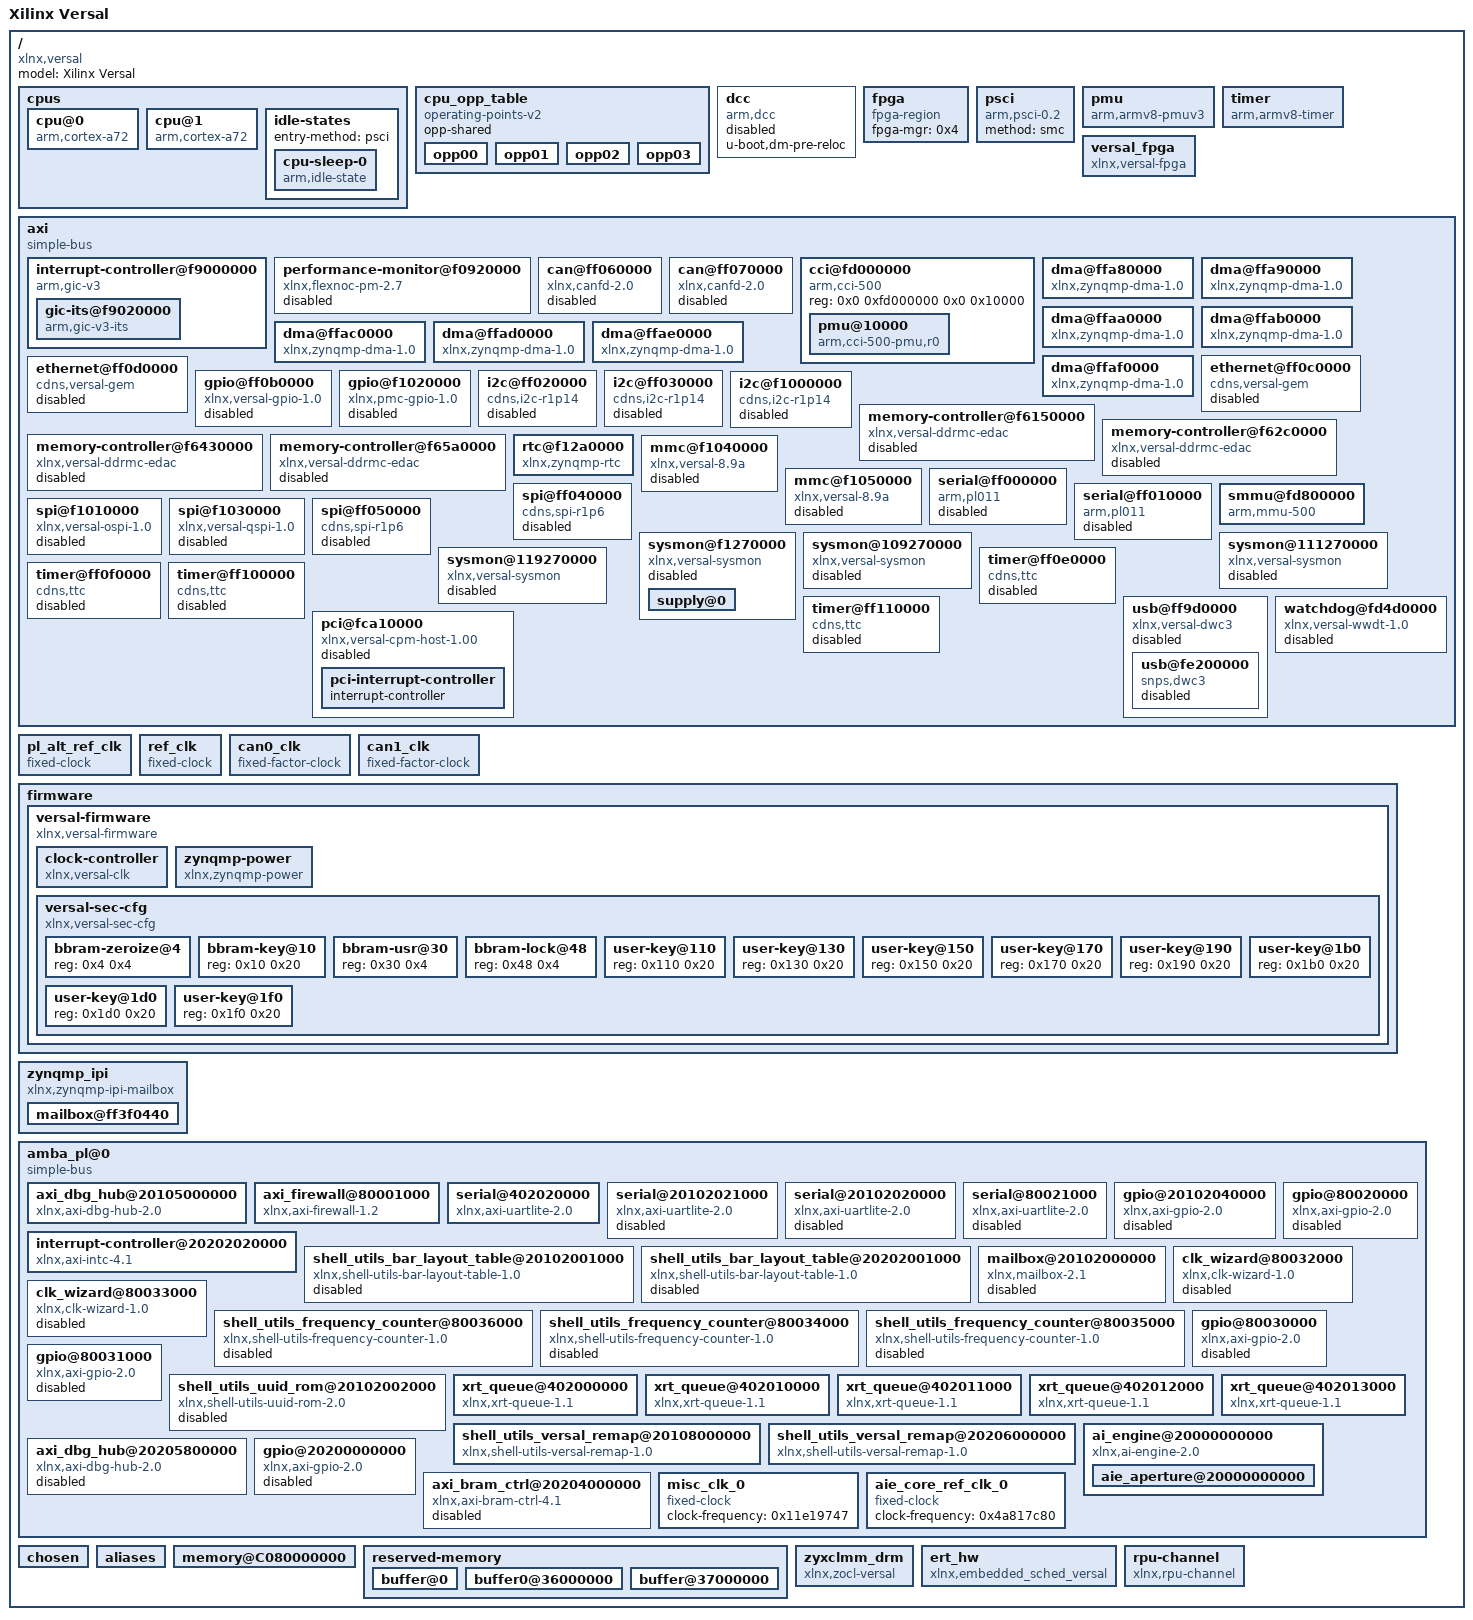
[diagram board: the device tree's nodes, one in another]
/dts-v1/;

/ {
	compatible = "xlnx,versal";
	#address-cells = <0x2>;
	#size-cells = <0x2>;
	model = "Xilinx Versal";

	cpus {
		#address-cells = <0x1>;
		#size-cells = <0x0>;

		cpu@0 {
			compatible = "arm,cortex-a72", "arm,armv8";
			device_type = "cpu";
			enable-method = "psci";
			operating-points-v2 = <0x1>;
			reg = <0x0>;
			cpu-idle-states = <0x2>;
			clocks = <0x3 0x4d>;
		};

		cpu@1 {
			compatible = "arm,cortex-a72", "arm,armv8";
			device_type = "cpu";
			enable-method = "psci";
			operating-points-v2 = <0x1>;
			reg = <0x1>;
			cpu-idle-states = <0x2>;
		};

		idle-states {
			entry-method = "psci";

			cpu-sleep-0 {
				compatible = "arm,idle-state";
				arm,psci-suspend-param = <0x40000000>;
				local-timer-stop;
				entry-latency-us = <0x12c>;
				exit-latency-us = <0x258>;
				min-residency-us = <0x2710>;
				phandle = <0x2>;
			};
		};
	};

	cpu_opp_table {
		compatible = "operating-points-v2";
		opp-shared;
		phandle = <0x1>;

		opp00 {
			opp-hz = <0x0 0x47868bf4>;
			opp-microvolt = <0xf4240>;
			clock-latency-ns = <0x7a120>;
		};

		opp01 {
			opp-hz = <0x0 0x23c345fa>;
			opp-microvolt = <0xf4240>;
			clock-latency-ns = <0x7a120>;
		};

		opp02 {
			opp-hz = <0x0 0x17d783fc>;
			opp-microvolt = <0xf4240>;
			clock-latency-ns = <0x7a120>;
		};

		opp03 {
			opp-hz = <0x0 0x11e1a2fd>;
			opp-microvolt = <0xf4240>;
			clock-latency-ns = <0x7a120>;
		};
	};

	dcc {
		compatible = "arm,dcc";
		status = "disabled";
		u-boot,dm-pre-reloc;
	};

	fpga {
		compatible = "fpga-region";
		fpga-mgr = <0x4>;
		#address-cells = <0x2>;
		#size-cells = <0x2>;
	};

	psci {
		compatible = "arm,psci-0.2";
		method = "smc";
	};

	pmu {
		compatible = "arm,armv8-pmuv3";
		interrupt-parent = <0x5>;
		interrupts = <0x1 0x7 0x304>;
	};

	timer {
		compatible = "arm,armv8-timer";
		interrupt-parent = <0x5>;
		interrupts = <0x1 0xd 0x4 0x1 0xe 0x4 0x1 0xb 0x4 0x1 0xa 0x4>;
	};

	versal_fpga {
		compatible = "xlnx,versal-fpga";
		phandle = <0x4>;
	};

	axi {
		compatible = "simple-bus";
		#address-cells = <0x2>;
		#size-cells = <0x2>;
		ranges;
		interrupt-parent = <0x5>;
		u-boot,dm-pre-reloc;

		interrupt-controller@f9000000 {
			compatible = "arm,gic-v3";
			#interrupt-cells = <0x3>;
			#address-cells = <0x2>;
			#size-cells = <0x2>;
			ranges;
			reg = <0x0 0xf9000000 0x0 0x80000 0x0 0xf9080000 0x0 0x80000>;
			interrupt-controller;
			interrupts = <0x1 0x9 0x4>;
			num_cpus = <0x2>;
			num_interrupts = <0x60>;
			phandle = <0x5>;

			gic-its@f9020000 {
				compatible = "arm,gic-v3-its";
				msi-controller;
				msi-cells = <0x1>;
				reg = <0x0 0xf9020000 0x0 0x20000>;
				phandle = <0xa>;
			};
		};

		performance-monitor@f0920000 {
			compatible = "xlnx,flexnoc-pm-2.7";
			status = "disabled";
			reg-names = "funnel", "baselpd", "basefpd";
			reg = <0x0 0xf0920000 0x0 0x1000 0x0 0xf0980000 0x0 0x9000 0x0 0xf0b80000 0x0 0x9000>;
		};

		can@ff060000 {
			compatible = "xlnx,canfd-2.0";
			status = "disabled";
			reg = <0x0 0xff060000 0x0 0x6000>;
			interrupts = <0x0 0x14 0x4>;
			clock-names = "can_clk", "s_axi_aclk";
			rx-fifo-depth = <0x40>;
			tx-mailbox-count = <0x20>;
			clocks = <0x6 0x3 0x52>;
			power-domains = <0x7 0x1822401f>;
		};

		can@ff070000 {
			compatible = "xlnx,canfd-2.0";
			status = "disabled";
			reg = <0x0 0xff070000 0x0 0x6000>;
			interrupts = <0x0 0x15 0x4>;
			clock-names = "can_clk", "s_axi_aclk";
			rx-fifo-depth = <0x40>;
			tx-mailbox-count = <0x20>;
			clocks = <0x8 0x3 0x52>;
			power-domains = <0x7 0x18224020>;
		};

		cci@fd000000 {
			compatible = "arm,cci-500";
			status = "okay";
			reg = <0x0 0xfd000000 0x0 0x10000>;
			ranges = <0x0 0x0 0xfd000000 0xa0000>;
			#address-cells = <0x1>;
			#size-cells = <0x1>;

			pmu@10000 {
				compatible = "arm,cci-500-pmu,r0";
				reg = <0x10000 0x90000>;
				interrupts = <0x0 0x6a 0x4 0x0 0x6a 0x4 0x0 0x6a 0x4 0x0 0x6a 0x4 0x0 0x6a 0x4 0x0 0x6a 0x4 0x0 0x6a 0x4 0x0 0x6a 0x4 0x0 0x6a 0x4>;
			};
		};

		dma@ffa80000 {
			compatible = "xlnx,zynqmp-dma-1.0";
			status = "okay";
			reg = <0x0 0xffa80000 0x0 0x1000>;
			interrupts = <0x0 0x3c 0x4>;
			clock-names = "clk_main", "clk_apb";
			#stream-id-cells = <0x1>;
			xlnx,bus-width = <0x40>;
			clocks = <0x3 0x51 0x3 0x52>;
			power-domains = <0x7 0x18224035>;
		};

		dma@ffa90000 {
			compatible = "xlnx,zynqmp-dma-1.0";
			status = "okay";
			reg = <0x0 0xffa90000 0x0 0x1000>;
			interrupts = <0x0 0x3d 0x4>;
			clock-names = "clk_main", "clk_apb";
			#stream-id-cells = <0x1>;
			xlnx,bus-width = <0x40>;
			clocks = <0x3 0x51 0x3 0x52>;
			power-domains = <0x7 0x18224036>;
		};

		dma@ffaa0000 {
			compatible = "xlnx,zynqmp-dma-1.0";
			status = "okay";
			reg = <0x0 0xffaa0000 0x0 0x1000>;
			interrupts = <0x0 0x3e 0x4>;
			clock-names = "clk_main", "clk_apb";
			#stream-id-cells = <0x1>;
			xlnx,bus-width = <0x40>;
			clocks = <0x3 0x51 0x3 0x52>;
			power-domains = <0x7 0x18224037>;
		};

		dma@ffab0000 {
			compatible = "xlnx,zynqmp-dma-1.0";
			status = "okay";
			reg = <0x0 0xffab0000 0x0 0x1000>;
			interrupts = <0x0 0x3f 0x4>;
			clock-names = "clk_main", "clk_apb";
			#stream-id-cells = <0x1>;
			xlnx,bus-width = <0x40>;
			clocks = <0x3 0x51 0x3 0x52>;
			power-domains = <0x7 0x18224038>;
		};

		dma@ffac0000 {
			compatible = "xlnx,zynqmp-dma-1.0";
			status = "okay";
			reg = <0x0 0xffac0000 0x0 0x1000>;
			interrupts = <0x0 0x40 0x4>;
			clock-names = "clk_main", "clk_apb";
			#stream-id-cells = <0x1>;
			xlnx,bus-width = <0x40>;
			clocks = <0x3 0x51 0x3 0x52>;
			power-domains = <0x7 0x18224039>;
		};

		dma@ffad0000 {
			compatible = "xlnx,zynqmp-dma-1.0";
			status = "okay";
			reg = <0x0 0xffad0000 0x0 0x1000>;
			interrupts = <0x0 0x41 0x4>;
			clock-names = "clk_main", "clk_apb";
			#stream-id-cells = <0x1>;
			xlnx,bus-width = <0x40>;
			clocks = <0x3 0x51 0x3 0x52>;
			power-domains = <0x7 0x1822403a>;
		};

		dma@ffae0000 {
			compatible = "xlnx,zynqmp-dma-1.0";
			status = "okay";
			reg = <0x0 0xffae0000 0x0 0x1000>;
			interrupts = <0x0 0x42 0x4>;
			clock-names = "clk_main", "clk_apb";
			#stream-id-cells = <0x1>;
			xlnx,bus-width = <0x40>;
			clocks = <0x3 0x51 0x3 0x52>;
			power-domains = <0x7 0x1822403b>;
		};

		dma@ffaf0000 {
			compatible = "xlnx,zynqmp-dma-1.0";
			status = "okay";
			reg = <0x0 0xffaf0000 0x0 0x1000>;
			interrupts = <0x0 0x43 0x4>;
			clock-names = "clk_main", "clk_apb";
			#stream-id-cells = <0x1>;
			xlnx,bus-width = <0x40>;
			clocks = <0x3 0x51 0x3 0x52>;
			power-domains = <0x7 0x1822403c>;
		};

		ethernet@ff0c0000 {
			compatible = "cdns,versal-gem", "cdns,gem";
			status = "disabled";
			reg = <0x0 0xff0c0000 0x0 0x1000>;
			interrupts = <0x0 0x38 0x4 0x0 0x38 0x4>;
			clock-names = "pclk", "hclk", "tx_clk", "rx_clk", "tsu_clk";
			#stream-id-cells = <0x1>;
			#address-cells = <0x1>;
			#size-cells = <0x0>;
			clocks = <0x3 0x52 0x3 0x58 0x3 0x31 0x3 0x30 0x3 0x2b>;
			power-domains = <0x7 0x18224019>;
		};

		ethernet@ff0d0000 {
			compatible = "cdns,versal-gem", "cdns,gem";
			status = "disabled";
			reg = <0x0 0xff0d0000 0x0 0x1000>;
			interrupts = <0x0 0x3a 0x4 0x0 0x3a 0x4>;
			clock-names = "pclk", "hclk", "tx_clk", "rx_clk", "tsu_clk";
			#stream-id-cells = <0x1>;
			#address-cells = <0x1>;
			#size-cells = <0x0>;
			clocks = <0x3 0x52 0x3 0x59 0x3 0x33 0x3 0x32 0x3 0x2b>;
			power-domains = <0x7 0x1822401a>;
		};

		gpio@ff0b0000 {
			compatible = "xlnx,versal-gpio-1.0";
			status = "disabled";
			reg = <0x0 0xff0b0000 0x0 0x1000>;
			interrupts = <0x0 0xd 0x4>;
			#gpio-cells = <0x2>;
			gpio-controller;
			#interrupt-cells = <0x2>;
			interrupt-controller;
			clocks = <0x3 0x52>;
			power-domains = <0x7 0x18224023>;
		};

		gpio@f1020000 {
			compatible = "xlnx,pmc-gpio-1.0";
			status = "disabled";
			reg = <0x0 0xf1020000 0x0 0x1000>;
			interrupts = <0x0 0x7a 0x4>;
			#gpio-cells = <0x2>;
			gpio-controller;
			#interrupt-cells = <0x2>;
			interrupt-controller;
			clocks = <0x3 0x3d>;
			power-domains = <0x7 0x1822402c>;
		};

		i2c@ff020000 {
			compatible = "cdns,i2c-r1p14", "cdns,i2c-r1p10";
			status = "disabled";
			reg = <0x0 0xff020000 0x0 0x1000>;
			interrupts = <0x0 0xe 0x4>;
			clock-frequency = <0x61a80>;
			#address-cells = <0x1>;
			#size-cells = <0x0>;
			clocks = <0x3 0x62>;
			power-domains = <0x7 0x1822401d>;
		};

		i2c@ff030000 {
			compatible = "cdns,i2c-r1p14", "cdns,i2c-r1p10";
			status = "disabled";
			reg = <0x0 0xff030000 0x0 0x1000>;
			interrupts = <0x0 0xf 0x4>;
			clock-frequency = <0x61a80>;
			#address-cells = <0x1>;
			#size-cells = <0x0>;
			clocks = <0x3 0x63>;
			power-domains = <0x7 0x1822401e>;
		};

		i2c@f1000000 {
			compatible = "cdns,i2c-r1p14", "cdns,i2c-r1p10";
			status = "disabled";
			reg = <0x0 0xf1000000 0x0 0x1000>;
			interrupts = <0x0 0x7b 0x4>;
			clock-frequency = <0x61a80>;
			#address-cells = <0x1>;
			#size-cells = <0x0>;
			clocks = <0x3 0x3e>;
			power-domains = <0x7 0x1822402d>;
		};

		memory-controller@f6150000 {
			compatible = "xlnx,versal-ddrmc-edac";
			status = "disabled";
			reg = <0x0 0xf6150000 0x0 0x2000 0x0 0xf6070000 0x0 0x20000>;
			reg-names = "ddrmc_base", "ddrmc_noc_base";
			interrupts = <0x0 0x93 0x4>;
			xlnx,mc-id = <0x0>;
		};

		memory-controller@f62c0000 {
			compatible = "xlnx,versal-ddrmc-edac";
			status = "disabled";
			reg = <0x0 0xf62c0000 0x0 0x2000 0x0 0xf6210000 0x0 0x20000>;
			reg-names = "ddrmc_base", "ddrmc_noc_base";
			interrupts = <0x0 0x93 0x4>;
			xlnx,mc-id = <0x1>;
		};

		memory-controller@f6430000 {
			compatible = "xlnx,versal-ddrmc-edac";
			status = "disabled";
			reg = <0x0 0xf6430000 0x0 0x2000 0x0 0xf6380000 0x0 0x20000>;
			reg-names = "ddrmc_base", "ddrmc_noc_base";
			interrupts = <0x0 0x93 0x4>;
			xlnx,mc-id = <0x2>;
		};

		memory-controller@f65a0000 {
			compatible = "xlnx,versal-ddrmc-edac";
			status = "disabled";
			reg = <0x0 0xf65a0000 0x0 0x2000 0x0 0xf64f0000 0x0 0x20000>;
			reg-names = "ddrmc_base", "ddrmc_noc_base";
			interrupts = <0x0 0x93 0x4>;
			xlnx,mc-id = <0x3>;
		};

		rtc@f12a0000 {
			compatible = "xlnx,zynqmp-rtc";
			status = "okay";
			reg = <0x0 0xf12a0000 0x0 0x100>;
			interrupt-names = "alarm", "sec";
			interrupts = <0x0 0x8e 0x4 0x0 0x8f 0x4>;
			calibration = <0x7fff>;
			power-domains = <0x7 0x18224034>;
		};

		mmc@f1040000 {
			compatible = "xlnx,versal-8.9a", "arasan,sdhci-8.9a";
			status = "disabled";
			reg = <0x0 0xf1040000 0x0 0x10000>;
			interrupts = <0x0 0x7e 0x4>;
			clock-names = "clk_xin", "clk_ahb";
			xlnx,device_id = <0x0>;
			#stream-id-cells = <0x1>;
			#clock-cells = <0x1>;
			clock-output-names = "clk_out_sd0", "clk_in_sd0";
			clocks = <0x3 0x3b 0x3 0x52>;
			power-domains = <0x7 0x1822402e>;
		};

		mmc@f1050000 {
			compatible = "xlnx,versal-8.9a", "arasan,sdhci-8.9a";
			status = "disabled";
			reg = <0x0 0xf1050000 0x0 0x10000>;
			interrupts = <0x0 0x80 0x4>;
			clock-names = "clk_xin", "clk_ahb";
			xlnx,device_id = <0x1>;
			#stream-id-cells = <0x1>;
			#clock-cells = <0x1>;
			clock-output-names = "clk_out_sd1", "clk_in_sd1";
			clocks = <0x3 0x3c 0x3 0x52>;
			power-domains = <0x7 0x1822402f>;
		};

		serial@ff000000 {
			compatible = "arm,pl011", "arm,sbsa-uart";
			status = "disabled";
			reg = <0x0 0xff000000 0x0 0x1000>;
			interrupts = <0x0 0x12 0x4>;
			clock-names = "uart_clk", "apb_clk";
			current-speed = <0x1c200>;
			u-boot,dm-pre-reloc;
			clocks = <0x3 0x5c 0x3 0x52>;
			power-domains = <0x7 0x18224021>;
			cts-override;
			device_type = "serial";
			port-number = <0x1>;
		};

		serial@ff010000 {
			compatible = "arm,pl011", "arm,sbsa-uart";
			status = "disabled";
			reg = <0x0 0xff010000 0x0 0x1000>;
			interrupts = <0x0 0x13 0x4>;
			clock-names = "uart_clk", "apb_clk";
			current-speed = <0x1c200>;
			u-boot,dm-pre-reloc;
			clocks = <0x3 0x5d 0x3 0x52>;
			power-domains = <0x7 0x18224022>;
			cts-override;
			device_type = "serial";
			port-number = <0x2>;
		};

		smmu@fd800000 {
			compatible = "arm,mmu-500";
			status = "okay";
			reg = <0x0 0xfd800000 0x0 0x40000>;
			stream-match-mask = <0x7c00>;
			#iommu-cells = <0x1>;
			#global-interrupts = <0x1>;
			interrupts = <0x0 0x6b 0x4 0x0 0x6b 0x4 0x0 0x6b 0x4 0x0 0x6b 0x4 0x0 0x6b 0x4 0x0 0x6b 0x4 0x0 0x6b 0x4 0x0 0x6b 0x4 0x0 0x6b 0x4 0x0 0x6b 0x4 0x0 0x6b 0x4 0x0 0x6b 0x4 0x0 0x6b 0x4 0x0 0x6b 0x4 0x0 0x6b 0x4 0x0 0x6b 0x4 0x0 0x6b 0x4 0x0 0x6b 0x4 0x0 0x6b 0x4 0x0 0x6b 0x4 0x0 0x6b 0x4 0x0 0x6b 0x4 0x0 0x6b 0x4 0x0 0x6b 0x4 0x0 0x6b 0x4 0x0 0x6b 0x4 0x0 0x6b 0x4 0x0 0x6b 0x4 0x0 0x6b 0x4 0x0 0x6b 0x4 0x0 0x6b 0x4 0x0 0x6b 0x4 0x0 0x6b 0x4>;
		};

		spi@f1010000 {
			compatible = "xlnx,versal-ospi-1.0", "cadence,qspi", "cdns,qspi-nor";
			status = "disabled";
			reg = <0x0 0xf1010000 0x0 0x10000 0x0 0xc0000000 0x0 0x20000000>;
			interrupts = <0x0 0x7c 0x4 0x0 0x7c 0x4>;
			cdns,fifo-depth = <0x100>;
			cdns,fifo-width = <0x4>;
			cdns,is-dma = <0x1>;
			cdns,is-stig-pgm = <0x1>;
			cdns,trigger-address = <0xc0000000>;
			#stream-id-cells = <0x1>;
			#address-cells = <0x1>;
			#size-cells = <0x0>;
			clocks = <0x3 0x3a>;
			power-domains = <0x7 0x1822402a>;
			is-dual = <0x0>;
			is-stacked = <0x0>;
		};

		spi@f1030000 {
			compatible = "xlnx,versal-qspi-1.0";
			status = "disabled";
			reg = <0x0 0xf1030000 0x0 0x1000>;
			interrupts = <0x0 0x7d 0x4 0x0 0x7d 0x4>;
			clock-names = "ref_clk", "pclk";
			#stream-id-cells = <0x1>;
			#address-cells = <0x1>;
			#size-cells = <0x0>;
			clocks = <0x3 0x39 0x3 0x52>;
			power-domains = <0x7 0x1822402b>;
		};

		spi@ff040000 {
			compatible = "cdns,spi-r1p6";
			status = "disabled";
			reg = <0x0 0xff040000 0x0 0x1000>;
			interrupts = <0x0 0x10 0x4>;
			clock-names = "ref_clk", "pclk";
			#address-cells = <0x1>;
			#size-cells = <0x0>;
			clocks = <0x3 0x5e 0x3 0x52>;
			power-domains = <0x7 0x1822401b>;
		};

		spi@ff050000 {
			compatible = "cdns,spi-r1p6";
			status = "disabled";
			reg = <0x0 0xff050000 0x0 0x1000>;
			interrupts = <0x0 0x11 0x4>;
			clock-names = "ref_clk", "pclk";
			#address-cells = <0x1>;
			#size-cells = <0x0>;
			clocks = <0x3 0x5f 0x3 0x52>;
			power-domains = <0x7 0x1822401c>;
		};

		sysmon@f1270000 {
			compatible = "xlnx,versal-sysmon";
			status = "disabled";
			reg = <0x0 0xf1270000 0x0 0x4000>;
			interrupts = <0x0 0x90 0x4>;
			xlnx,numchannels = [01];
			#address-cells = <0x1>;
			#size-cells = <0x0>;

			supply@0 {
				reg = <0x0>;
				xlnx,name = "vccint";
			};
		};

		sysmon@109270000 {
			compatible = "xlnx,versal-sysmon";
			#address-cells = <0x2>;
			#size-cells = <0x2>;
			status = "disabled";
			reg = <0x1 0x9270000 0x0 0x4000>;
			xlnx,numchannels = [00];
		};

		sysmon@111270000 {
			compatible = "xlnx,versal-sysmon";
			#address-cells = <0x2>;
			#size-cells = <0x2>;
			status = "disabled";
			reg = <0x1 0x11270000 0x0 0x4000>;
			xlnx,numchannels = [00];
		};

		sysmon@119270000 {
			compatible = "xlnx,versal-sysmon";
			#address-cells = <0x2>;
			#size-cells = <0x2>;
			status = "disabled";
			reg = <0x1 0x19270000 0x0 0x4000>;
			xlnx,numchannels = [00];
		};

		timer@ff0e0000 {
			compatible = "cdns,ttc";
			status = "disabled";
			interrupts = <0x0 0x25 0x4 0x0 0x26 0x4 0x0 0x27 0x4>;
			reg = <0x0 0xff0e0000 0x0 0x1000>;
			timer-width = <0x20>;
			clocks = <0x3 0x27 0x3 0x52>;
			power-domains = <0x7 0x18224024>;
		};

		timer@ff0f0000 {
			compatible = "cdns,ttc";
			status = "disabled";
			interrupts = <0x0 0x28 0x4 0x0 0x29 0x4 0x0 0x2a 0x4>;
			reg = <0x0 0xff0f0000 0x0 0x1000>;
			timer-width = <0x20>;
			clocks = <0x3 0x28 0x3 0x52>;
			power-domains = <0x7 0x18224025>;
		};

		timer@ff100000 {
			compatible = "cdns,ttc";
			status = "disabled";
			interrupts = <0x0 0x2b 0x4 0x0 0x2c 0x4 0x0 0x2d 0x4>;
			reg = <0x0 0xff100000 0x0 0x1000>;
			timer-width = <0x20>;
			clocks = <0x3 0x29 0x3 0x52>;
			power-domains = <0x7 0x18224026>;
		};

		timer@ff110000 {
			compatible = "cdns,ttc";
			status = "disabled";
			interrupts = <0x0 0x2e 0x4 0x0 0x2f 0x4 0x0 0x30 0x4>;
			reg = <0x0 0xff110000 0x0 0x1000>;
			timer-width = <0x20>;
			clocks = <0x3 0x2a 0x3 0x52>;
			power-domains = <0x7 0x18224027>;
		};

		usb@ff9d0000 {
			compatible = "xlnx,versal-dwc3";
			status = "disabled";
			reg = <0x0 0xff9d0000 0x0 0x100>;
			clock-names = "bus_clk", "ref_clk";
			ranges;
			#address-cells = <0x2>;
			#size-cells = <0x2>;
			clocks = <0x3 0x5b 0x3 0x68>;
			power-domains = <0x7 0x18224018>;

			usb@fe200000 {
				compatible = "snps,dwc3";
				status = "disabled";
				reg = <0x0 0xfe200000 0x0 0x10000>;
				interrupt-names = "dwc_usb3", "otg", "usb-wakeup";
				interrupts = <0x0 0x16 0x4 0x0 0x1a 0x4 0x0 0x4a 0x4>;
				#stream-id-cells = <0x1>;
				snps,dis_u2_susphy_quirk;
				snps,dis_u3_susphy_quirk;
				snps,quirk-frame-length-adjustment = <0x20>;
				snps,refclk_fladj;
				snps,mask_phy_reset;
			};
		};

		pci@fca10000 {
			#address-cells = <0x3>;
			#interrupt-cells = <0x1>;
			#size-cells = <0x2>;
			compatible = "xlnx,versal-cpm-host-1.00";
			status = "disabled";
			interrupt-map = <0x0 0x0 0x0 0x1 0x9 0x0 0x0 0x0 0x0 0x2 0x9 0x1 0x0 0x0 0x0 0x3 0x9 0x2 0x0 0x0 0x0 0x4 0x9 0x3>;
			interrupt-map-mask = <0x0 0x0 0x0 0x7>;
			interrupt-names = "misc";
			interrupts = <0x0 0x48 0x4>;
			ranges = <0x2000000 0x0 0xe0000000 0x0 0xe0000000 0x0 0x10000000 0x43000000 0x80 0x0 0x80 0x0 0x0 0x80000000>;
			msi-map = <0x0 0xa 0x0 0x10000>;
			reg = <0x0 0xfca10000 0x0 0x1000 0x6 0x0 0x0 0x1000000>;
			reg-names = "cpm_slcr", "cfg";

			pci-interrupt-controller {
				#address-cells = <0x0>;
				#interrupt-cells = <0x1>;
				interrupt-controller;
				phandle = <0x9>;
			};
		};

		watchdog@fd4d0000 {
			compatible = "xlnx,versal-wwdt-1.0";
			status = "disabled";
			reg = <0x0 0xfd4d0000 0x0 0x10000>;
			interrupt-names = "wdt", "wwdt_reset_pending";
			interrupts = <0x0 0x64 0x1 0x0 0x6d 0x1>;
			timeout-sec = <0x1e>;
			pretimeout-sec = <0x19>;
			clocks = <0x3 0x52>;
			power-domains = <0x7 0x18224029>;
		};
	};

	pl_alt_ref_clk {
		u-boot,dm-pre-reloc;
		compatible = "fixed-clock";
		#clock-cells = <0x0>;
		clock-frequency = <0x1fca055>;
		phandle = <0xc>;
	};

	ref_clk {
		u-boot,dm-pre-reloc;
		compatible = "fixed-clock";
		#clock-cells = <0x0>;
		clock-frequency = <0x1fca055>;
		phandle = <0xb>;
	};

	can0_clk {
		#clock-cells = <0x0>;
		compatible = "fixed-factor-clock";
		clocks = <0x3 0x60>;
		clock-div = <0x2>;
		clock-mult = <0x1>;
		phandle = <0x6>;
	};

	can1_clk {
		#clock-cells = <0x0>;
		compatible = "fixed-factor-clock";
		clocks = <0x3 0x61>;
		clock-div = <0x2>;
		clock-mult = <0x1>;
		phandle = <0x8>;
	};

	firmware {

		versal-firmware {
			compatible = "xlnx,versal-firmware";
			interrupt-parent = <0x5>;
			u-boot,dm-pre-reloc;
			method = "smc";
			#power-domain-cells = <0x1>;
			phandle = <0x7>;

			clock-controller {
				u-boot,dm-pre-reloc;
				#clock-cells = <0x1>;
				compatible = "xlnx,versal-clk";
				clocks = <0xb 0xc>;
				clock-names = "ref_clk", "pl_alt_ref_clk";
				phandle = <0x3>;
			};

			zynqmp-power {
				compatible = "xlnx,zynqmp-power";
				interrupt-parent = <0x5>;
				interrupts = <0x0 0x1e 0x4>;
				mboxes = <0xd 0x0 0xd 0x1>;
				mbox-names = "tx", "rx";
			};

			versal-sec-cfg {
				compatible = "xlnx,versal-sec-cfg";
				#address-cells = <0x1>;
				#size-cells = <0x1>;

				bbram-zeroize@4 {
					reg = <0x4 0x4>;
				};

				bbram-key@10 {
					reg = <0x10 0x20>;
				};

				bbram-usr@30 {
					reg = <0x30 0x4>;
				};

				bbram-lock@48 {
					reg = <0x48 0x4>;
				};

				user-key@110 {
					reg = <0x110 0x20>;
				};

				user-key@130 {
					reg = <0x130 0x20>;
				};

				user-key@150 {
					reg = <0x150 0x20>;
				};

				user-key@170 {
					reg = <0x170 0x20>;
				};

				user-key@190 {
					reg = <0x190 0x20>;
				};

				user-key@1b0 {
					reg = <0x1b0 0x20>;
				};

				user-key@1d0 {
					reg = <0x1d0 0x20>;
				};

				user-key@1f0 {
					reg = <0x1f0 0x20>;
				};
			};
		};
	};

	zynqmp_ipi {
		compatible = "xlnx,zynqmp-ipi-mailbox";
		interrupt-parent = <0x5>;
		interrupts = <0x0 0x1e 0x4>;
		xlnx,ipi-id = <0x2>;
		#address-cells = <0x2>;
		#size-cells = <0x2>;
		ranges;

		mailbox@ff3f0440 {
			reg = <0x0 0xff3f0440 0x0 0x20 0x0 0xff3f0460 0x0 0x20 0x0 0xff3f0280 0x0 0x20 0x0 0xff3f02a0 0x0 0x20>;
			reg-names = "local_request_region", "local_response_region", "remote_request_region", "remote_response_region";
			#mbox-cells = <0x1>;
			xlnx,ipi-id = <0x1>;
			phandle = <0xd>;
		};
	};

	amba_pl@0 {
		#address-cells = <0x2>;
		#size-cells = <0x2>;
		compatible = "simple-bus";
		ranges;

		axi_dbg_hub@20105000000 {
			clock-names = "aclk";
			clocks = <0x3 0x41>;
			compatible = "xlnx,axi-dbg-hub-2.0";
			reg = <0x201 0x5000000 0x0 0x200000>;
			xlnx,addr-offset = <0x201 0x5000000>;
			xlnx,addr-range = <0x200000>;
			xlnx,axi-addr-width = <0x40>;
			xlnx,axi-data-width = <0x80>;
			xlnx,axi-id-width = <0x2>;
			xlnx,axis-tdata-width = <0x20>;
			xlnx,num-debug-cores = <0x0>;
			xlnx,num-rd-outstanding-txn = <0x1>;
			xlnx,num-wr-outstanding-txn = <0x1>;
		};

		axi_firewall@80001000 {
			clock-names = "aclk";
			clocks = <0x3 0x41>;
			compatible = "xlnx,axi-firewall-1.2";
			reg = <0x0 0x80001000 0x0 0x1000>;
			xlnx,addr-width = <0x40>;
			xlnx,aruser-width = <0x0>;
			xlnx,awuser-width = <0x0>;
			xlnx,buser-width = <0x0>;
			xlnx,enable-ctl-clock = <0x0>;
			xlnx,enable-initial-delay = <0x1>;
			xlnx,enable-pipelining = <0x1>;
			xlnx,enable-prescaler = <0x1>;
			xlnx,enable-protocol-checks = <0x1>;
			xlnx,enable-timeout-checks = <0x1>;
			xlnx,firewall-mode = <0x0>;
			xlnx,id-width = <0x0>;
			xlnx,mask-err-resp = <0x1>;
			xlnx,num-read-outstanding = <0x20>;
			xlnx,num-read-threads = <0x1>;
			xlnx,num-write-outstanding = <0x20>;
			xlnx,num-write-threads = <0x1>;
			xlnx,protocol = <0x2>;
			xlnx,rdata-width = <0x20>;
			xlnx,ruser-width = <0x0>;
			xlnx,wdata-width = <0x20>;
			xlnx,wuser-width = <0x0>;
		};

		serial@402020000 {
			clock-names = "s_axi_aclk";
			clocks = <0x3 0x41>;
			compatible = "xlnx,axi-uartlite-2.0", "xlnx,xps-uartlite-1.00.a";
			current-speed = <0x38400>;
			device_type = "serial";
			interrupt-names = "interrupt";
			interrupt-parent = <0x5>;
			interrupts = <0x0 0x5e 0x1>;
			port-number = <0x0>;
			reg = <0x4 0x2020000 0x0 0x1000>;
			xlnx,baudrate = <0x38400>;
			xlnx,data-bits = <0x8>;
			xlnx,odd-parity = <0x0>;
			xlnx,s-axi-aclk-freq-hz-d = "100.0";
			xlnx,use-parity = <0x0>;
		};

		serial@20102021000 {
			status = "disabled";
			clock-names = "s_axi_aclk";
			clocks = <0x3 0x41>;
			compatible = "xlnx,axi-uartlite-2.0", "xlnx,xps-uartlite-1.00.a";
			current-speed = <0x38400>;
			device_type = "serial";
			port-number = <0x2>;
			reg = <0x201 0x2021000 0x0 0x1000>;
			xlnx,baudrate = <0x38400>;
			xlnx,data-bits = <0x8>;
			xlnx,odd-parity = <0x0>;
			xlnx,s-axi-aclk-freq-hz-d = "100.0";
			xlnx,use-parity = <0x0>;
		};

		serial@20102020000 {
			status = "disabled";
			clock-names = "s_axi_aclk";
			clocks = <0x3 0x41>;
			compatible = "xlnx,axi-uartlite-2.0", "xlnx,xps-uartlite-1.00.a";
			current-speed = <0x38400>;
			device_type = "serial";
			port-number = <0x3>;
			reg = <0x201 0x2020000 0x0 0x1000>;
			xlnx,baudrate = <0x38400>;
			xlnx,data-bits = <0x8>;
			xlnx,odd-parity = <0x0>;
			xlnx,s-axi-aclk-freq-hz-d = "100.0";
			xlnx,use-parity = <0x0>;
		};

		serial@80021000 {
			status = "disabled";
			clock-names = "s_axi_aclk";
			clocks = <0x3 0x41>;
			compatible = "xlnx,axi-uartlite-2.0", "xlnx,xps-uartlite-1.00.a";
			current-speed = <0x38400>;
			device_type = "serial";
			interrupt-names = "interrupt";
			interrupt-parent = <0x5>;
			interrupts = <0x0 0x57 0x1>;
			port-number = <0x4>;
			reg = <0x0 0x80021000 0x0 0x1000>;
			xlnx,baudrate = <0x38400>;
			xlnx,data-bits = <0x8>;
			xlnx,odd-parity = <0x0>;
			xlnx,s-axi-aclk-freq-hz-d = "100.0";
			xlnx,use-parity = <0x0>;
		};

		gpio@20102040000 {
			status = "disabled";
			#gpio-cells = <0x2>;
			clock-names = "s_axi_aclk";
			clocks = <0x3 0x41>;
			compatible = "xlnx,axi-gpio-2.0", "xlnx,xps-gpio-1.00.a";
			gpio-controller;
			reg = <0x201 0x2040000 0x0 0x1000>;
			xlnx,all-inputs = <0x0>;
			xlnx,all-inputs-2 = <0x1>;
			xlnx,all-outputs = <0x1>;
			xlnx,all-outputs-2 = <0x0>;
			xlnx,dout-default = <0x0>;
			xlnx,dout-default-2 = <0x0>;
			xlnx,gpio-width = <0x1>;
			xlnx,gpio2-width = <0x1>;
			xlnx,interrupt-present = <0x0>;
			xlnx,is-dual = <0x1>;
			xlnx,tri-default = <0xffffffff>;
			xlnx,tri-default-2 = <0xffffffff>;
		};

		gpio@80020000 {
			status = "disabled";
			#gpio-cells = <0x2>;
			clock-names = "s_axi_aclk";
			clocks = <0x3 0x41>;
			compatible = "xlnx,axi-gpio-2.0", "xlnx,xps-gpio-1.00.a";
			gpio-controller;
			reg = <0x0 0x80020000 0x0 0x1000>;
			xlnx,all-inputs = <0x0>;
			xlnx,all-inputs-2 = <0x1>;
			xlnx,all-outputs = <0x1>;
			xlnx,all-outputs-2 = <0x0>;
			xlnx,dout-default = <0x0>;
			xlnx,dout-default-2 = <0x0>;
			xlnx,gpio-width = <0x2>;
			xlnx,gpio2-width = <0x2>;
			xlnx,interrupt-present = <0x0>;
			xlnx,is-dual = <0x1>;
			xlnx,tri-default = <0xffffffff>;
			xlnx,tri-default-2 = <0xffffffff>;
		};

		interrupt-controller@20202020000 {
			#interrupt-cells = <0x2>;
			clock-names = "s_axi_aclk";
			clocks = <0x3 0x41>;
			compatible = "xlnx,axi-intc-4.1", "xlnx,xps-intc-1.00.a";
			interrupt-controller;
			interrupt-names = "irq";
			interrupt-parent = <0x5>;
			interrupts = <0x0 0x5d 0x4>;
			reg = <0x202 0x2020000 0x0 0x1000>;
			xlnx,kind-of-intr = <0xffffffff>;
			xlnx,num-intr-inputs = <0x20>;
		};

		shell_utils_bar_layout_table@20102001000 {
			status = "disabled";
			clock-names = "S_AXI_ACLK";
			clocks = <0x3 0x41>;
			compatible = "xlnx,shell-utils-bar-layout-table-1.0";
			reg = <0x201 0x2001000 0x0 0x1000>;
			xlnx,entry-addr-0 = <0x0 0x2002000>;
			xlnx,entry-addr-1 = <0x0 0x2000000>;
			xlnx,entry-addr-2 = <0x0 0x2010000>;
			xlnx,entry-addr-3 = <0x0 0x8000000>;
			xlnx,entry-addr-4 = <0x0 0x0>;
			xlnx,entry-addr-5 = <0x0 0x0>;
			xlnx,entry-bar-0 = <0x0>;
			xlnx,entry-bar-1 = <0x0>;
			xlnx,entry-bar-2 = <0x0>;
			xlnx,entry-bar-3 = <0x0>;
			xlnx,entry-bar-4 = <0x0>;
			xlnx,entry-bar-5 = <0x0>;
			xlnx,entry-major-version-0 = <0x1>;
			xlnx,entry-major-version-1 = <0x1>;
			xlnx,entry-major-version-2 = <0x1>;
			xlnx,entry-major-version-3 = <0x1>;
			xlnx,entry-major-version-4 = <0x0>;
			xlnx,entry-major-version-5 = <0x0>;
			xlnx,entry-minor-version-0 = <0x0>;
			xlnx,entry-minor-version-1 = <0x0>;
			xlnx,entry-minor-version-2 = <0x1>;
			xlnx,entry-minor-version-3 = <0x0>;
			xlnx,entry-minor-version-4 = <0x0>;
			xlnx,entry-minor-version-5 = <0x0>;
			xlnx,entry-rsvd0-0 = <0x0>;
			xlnx,entry-rsvd0-1 = <0x3>;
			xlnx,entry-rsvd0-2 = <0x0>;
			xlnx,entry-rsvd0-3 = <0x0>;
			xlnx,entry-rsvd0-4 = <0x0>;
			xlnx,entry-rsvd0-5 = <0x0>;
			xlnx,entry-type-0 = <0x50>;
			xlnx,entry-type-1 = <0x53>;
			xlnx,entry-type-2 = <0x54>;
			xlnx,entry-type-3 = <0x55>;
			xlnx,entry-type-4 = <0x0>;
			xlnx,entry-type-5 = <0x0>;
			xlnx,entry-version-type-0 = <0x1>;
			xlnx,entry-version-type-1 = <0x1>;
			xlnx,entry-version-type-2 = <0x1>;
			xlnx,entry-version-type-3 = <0x1>;
			xlnx,entry-version-type-4 = <0x0>;
			xlnx,entry-version-type-5 = <0x0>;
			xlnx,num-table-entries = <0x4>;
			xlnx,xdevicefamily = "versal";
		};

		shell_utils_bar_layout_table@20202001000 {
			status = "disabled";
			clock-names = "S_AXI_ACLK";
			clocks = <0x3 0x41>;
			compatible = "xlnx,shell-utils-bar-layout-table-1.0";
			reg = <0x202 0x2001000 0x0 0x1000>;
			xlnx,entry-addr-0 = <0x0 0x2000000>;
			xlnx,entry-addr-1 = <0x0 0x0>;
			xlnx,entry-addr-2 = <0x0 0x0>;
			xlnx,entry-addr-3 = <0x0 0x0>;
			xlnx,entry-addr-4 = <0x0 0x0>;
			xlnx,entry-addr-5 = <0x0 0x0>;
			xlnx,entry-bar-0 = <0x2>;
			xlnx,entry-bar-1 = <0x0>;
			xlnx,entry-bar-2 = <0x0>;
			xlnx,entry-bar-3 = <0x0>;
			xlnx,entry-bar-4 = <0x0>;
			xlnx,entry-bar-5 = <0x0>;
			xlnx,entry-major-version-0 = <0x1>;
			xlnx,entry-major-version-1 = <0x0>;
			xlnx,entry-major-version-2 = <0x0>;
			xlnx,entry-major-version-3 = <0x0>;
			xlnx,entry-major-version-4 = <0x0>;
			xlnx,entry-major-version-5 = <0x0>;
			xlnx,entry-minor-version-0 = <0x0>;
			xlnx,entry-minor-version-1 = <0x0>;
			xlnx,entry-minor-version-2 = <0x0>;
			xlnx,entry-minor-version-3 = <0x0>;
			xlnx,entry-minor-version-4 = <0x0>;
			xlnx,entry-minor-version-5 = <0x0>;
			xlnx,entry-rsvd0-0 = <0x1>;
			xlnx,entry-rsvd0-1 = <0x0>;
			xlnx,entry-rsvd0-2 = <0x0>;
			xlnx,entry-rsvd0-3 = <0x0>;
			xlnx,entry-rsvd0-4 = <0x0>;
			xlnx,entry-rsvd0-5 = <0x0>;
			xlnx,entry-type-0 = <0x53>;
			xlnx,entry-type-1 = <0x0>;
			xlnx,entry-type-2 = <0x0>;
			xlnx,entry-type-3 = <0x0>;
			xlnx,entry-type-4 = <0x0>;
			xlnx,entry-type-5 = <0x0>;
			xlnx,entry-version-type-0 = <0x1>;
			xlnx,entry-version-type-1 = <0x0>;
			xlnx,entry-version-type-2 = <0x0>;
			xlnx,entry-version-type-3 = <0x0>;
			xlnx,entry-version-type-4 = <0x0>;
			xlnx,entry-version-type-5 = <0x0>;
			xlnx,num-table-entries = <0x1>;
			xlnx,xdevicefamily = "versal";
		};

		mailbox@20102000000 {
			status = "disabled";
			clock-names = "S0_AXI_ACLK", "S1_AXI_ACLK";
			clocks = <0x3 0x41 0x3 0x41>;
			compatible = "xlnx,mailbox-2.1";
			reg = <0x201 0x2000000 0x0 0x1000 0x202 0x2000000 0x0 0x1000>;
			xlnx,async-clks = <0x0>;
			xlnx,async-interrupts = <0x1>;
			xlnx,enable-bus-error = <0x0>;
			xlnx,ext-reset-high = <0x1>;
			xlnx,impl-style = <0x0>;
			xlnx,interconnect-port-0 = <0x2>;
			xlnx,interconnect-port-1 = <0x2>;
			xlnx,mailbox-depth = <0x10>;
			xlnx,num-sync-ff = <0x2>;
			xlnx,read-clock-period-0 = <0x0>;
			xlnx,read-clock-period-1 = <0x0>;
			xlnx,s0-axi-aclk-freq-mhz = "100.0";
			xlnx,s0-axi-addr-width = <0x20>;
			xlnx,s0-axi-data-width = <0x20>;
			xlnx,s1-axi-aclk-freq-mhz = "100.0";
			xlnx,s1-axi-addr-width = <0x20>;
			xlnx,s1-axi-data-width = <0x20>;
		};

		clk_wizard@80032000 {
			status = "disabled";
			#clock-cells = <0x1>;
			clock-names = "s_axi_aclk", "clk_in1";
			clock-output-names = "0x80032000-clk_out1";
			clocks = <0x3 0x41 0x3 0x42>;
			compatible = "xlnx,clk-wizard-1.0", "xlnx,clocking-wizard";
			reg = <0x0 0x80032000 0x0 0x1000>;
			speed-grade = <0x2>;
		};

		clk_wizard@80033000 {
			status = "disabled";
			#clock-cells = <0x1>;
			clock-names = "s_axi_aclk", "clk_in1";
			clock-output-names = "0x80033000-clk_out1";
			clocks = <0x3 0x41 0x3 0x42>;
			compatible = "xlnx,clk-wizard-1.0", "xlnx,clocking-wizard";
			reg = <0x0 0x80033000 0x0 0x1000>;
			speed-grade = <0x2>;
		};

		shell_utils_frequency_counter@80036000 {
			status = "disabled";
			clock-names = "s_axi_aclk";
			clocks = <0x3 0x42>;
			compatible = "xlnx,shell-utils-frequency-counter-1.0";
			reg = <0x0 0x80036000 0x0 0x1000>;
		};

		shell_utils_frequency_counter@80034000 {
			status = "disabled";
			clock-names = "s_axi_aclk";
			clocks = <0x3 0x42>;
			compatible = "xlnx,shell-utils-frequency-counter-1.0";
			reg = <0x0 0x80034000 0x0 0x1000>;
		};

		shell_utils_frequency_counter@80035000 {
			status = "disabled";
			clock-names = "s_axi_aclk";
			clocks = <0x3 0x42>;
			compatible = "xlnx,shell-utils-frequency-counter-1.0";
			reg = <0x0 0x80035000 0x0 0x1000>;
		};

		gpio@80030000 {
			status = "disabled";
			#gpio-cells = <0x2>;
			clock-names = "s_axi_aclk";
			clocks = <0x3 0x41>;
			compatible = "xlnx,axi-gpio-2.0", "xlnx,xps-gpio-1.00.a";
			gpio-controller;
			reg = <0x0 0x80030000 0x0 0x1000>;
			xlnx,all-inputs = <0x0>;
			xlnx,all-inputs-2 = <0x1>;
			xlnx,all-outputs = <0x1>;
			xlnx,all-outputs-2 = <0x0>;
			xlnx,dout-default = <0x10000ff>;
			xlnx,dout-default-2 = <0x0>;
			xlnx,gpio-width = <0x20>;
			xlnx,gpio2-width = <0x20>;
			xlnx,interrupt-present = <0x0>;
			xlnx,is-dual = <0x1>;
			xlnx,tri-default = <0xffffffff>;
			xlnx,tri-default-2 = <0xffffffff>;
		};

		gpio@80031000 {
			status = "disabled";
			#gpio-cells = <0x2>;
			clock-names = "s_axi_aclk";
			clocks = <0x3 0x41>;
			compatible = "xlnx,axi-gpio-2.0", "xlnx,xps-gpio-1.00.a";
			gpio-controller;
			reg = <0x0 0x80031000 0x0 0x1000>;
			xlnx,all-inputs = <0x1>;
			xlnx,all-inputs-2 = <0x0>;
			xlnx,all-outputs = <0x0>;
			xlnx,all-outputs-2 = <0x1>;
			xlnx,dout-default = <0x0>;
			xlnx,dout-default-2 = <0x0>;
			xlnx,gpio-width = <0x20>;
			xlnx,gpio2-width = <0x20>;
			xlnx,interrupt-present = <0x0>;
			xlnx,is-dual = <0x1>;
			xlnx,tri-default = <0xffffffff>;
			xlnx,tri-default-2 = <0xffffffff>;
		};

		shell_utils_uuid_rom@20102002000 {
			status = "disabled";
			clock-names = "S_AXI_ACLK";
			clocks = <0x3 0x41>;
			compatible = "xlnx,shell-utils-uuid-rom-2.0";
			reg = <0x201 0x2002000 0x0 0x1000>;
			xlnx,initial-uuid = <0x0>;
			xlnx,memory-init = <0x0>;
			xlnx,xdevicefamily = "versal";
		};

		xrt_queue@402000000 {
			clock-names = "s00_axi_aclk";
			clocks = <0x3 0x41>;
			compatible = "xlnx,xrt-queue-1.1";
			reg = <0x4 0x2000000 0x0 0x1000>;
			xlnx,include-bram = <0x0>;
			xlnx,s00-axi-addr-width = <0x9>;
			xlnx,s00-axi-data-width = <0x20>;
			xlnx,s02-axi-mem-addr-width = <0xb>;
			xlnx,s02-axi-mem-data-width = <0x20>;
			xlnx,s02-axi-mem-id-width = <0x1>;
			interrupt-parent = <0x5>;
			interrupts = <0x0 0x5c 0x1>;
			phandle = <0x3f>;
		};

		xrt_queue@402010000 {
			clock-names = "s00_axi_aclk";
			clocks = <0x3 0x41>;
			compatible = "xlnx,xrt-queue-1.1";
			reg = <0x4 0x2010000 0x0 0x1000>;
			xlnx,include-bram = <0x0>;
			xlnx,s00-axi-addr-width = <0x9>;
			xlnx,s00-axi-data-width = <0x20>;
			xlnx,s02-axi-mem-addr-width = <0xb>;
			xlnx,s02-axi-mem-data-width = <0x20>;
			xlnx,s02-axi-mem-id-width = <0x1>;
			interrupt-parent = <0x5>;
			interrupts = <0x0 0x5f 0x1>;
			phandle = <0x3d>;
		};

		xrt_queue@402011000 {
			clock-names = "s00_axi_aclk";
			clocks = <0x3 0x41>;
			compatible = "xlnx,xrt-queue-1.1";
			reg = <0x4 0x2011000 0x0 0x1000>;
			xlnx,include-bram = <0x0>;
			xlnx,s00-axi-addr-width = <0x9>;
			xlnx,s00-axi-data-width = <0x20>;
			xlnx,s02-axi-mem-addr-width = <0xb>;
			xlnx,s02-axi-mem-data-width = <0x20>;
			xlnx,s02-axi-mem-id-width = <0x1>;
			interrupt-parent = <0x5>;
			interrupts = <0x0 0x60 0x1>;
			phandle = <0x3c>;
		};

		xrt_queue@402012000 {
			clock-names = "s00_axi_aclk";
			clocks = <0x3 0x41>;
			compatible = "xlnx,xrt-queue-1.1";
			reg = <0x4 0x2012000 0x0 0x1000>;
			xlnx,include-bram = <0x0>;
			xlnx,s00-axi-addr-width = <0x9>;
			xlnx,s00-axi-data-width = <0x20>;
			xlnx,s02-axi-mem-addr-width = <0xb>;
			xlnx,s02-axi-mem-data-width = <0x20>;
			xlnx,s02-axi-mem-id-width = <0x1>;
			interrupt-parent = <0x5>;
			interrupts = <0x0 0x61 0x1>;
			phandle = <0x3b>;
		};

		xrt_queue@402013000 {
			clock-names = "s00_axi_aclk";
			clocks = <0x3 0x41>;
			compatible = "xlnx,xrt-queue-1.1";
			reg = <0x4 0x2013000 0x0 0x1000>;
			xlnx,include-bram = <0x0>;
			xlnx,s00-axi-addr-width = <0x9>;
			xlnx,s00-axi-data-width = <0x20>;
			xlnx,s02-axi-mem-addr-width = <0xb>;
			xlnx,s02-axi-mem-data-width = <0x20>;
			xlnx,s02-axi-mem-id-width = <0x1>;
			interrupt-parent = <0x5>;
			interrupts = <0x0 0x62 0x1>;
			phandle = <0x3a>;
		};

		shell_utils_versal_remap@20108000000 {
			clock-names = "AXI_ACLK";
			clocks = <0x3 0x41>;
			compatible = "xlnx,shell-utils-versal-remap-1.0";
			reg = <0x201 0x8000000 0x0 0x8000000>;
			xlnx,master-addr = <0x3800>;
			xlnx,transparent-bits = <0x1b>;
			xlnx,xdevicefamily = "versal";
		};

		shell_utils_versal_remap@20206000000 {
			clock-names = "AXI_ACLK";
			clocks = <0x3 0x41>;
			compatible = "xlnx,shell-utils-versal-remap-1.0";
			reg = <0x202 0x6000000 0x0 0x1000000>;
			xlnx,master-addr = <0x3600>;
			xlnx,transparent-bits = <0x18>;
			xlnx,xdevicefamily = "versal";
		};

		ai_engine@20000000000 {
			#address-cells = <0x2>;
			#size-cells = <0x2>;
			clock-names = "aclk0";
			clocks = <0xe>;
			compatible = "xlnx,ai-engine-2.0", "xlnx,ai-engine-v2.0";
			power-domains = <0x7 0x18224072>;
			ranges;
			reg = <0x200 0x0 0x1 0x0>;
			xlnx,aie-gen = [01];
			xlnx,core-rows = [01 08];
			xlnx,mem-rows = [00 00];
			xlnx,shim-rows = [00 01];

			aie_aperture@20000000000 {
				#address-cells = <0x2>;
				#size-cells = <0x2>;
				interrupt-names = "interrupt1", "interrupt2", "interrupt3";
				interrupt-parent = <0x5>;
				interrupts = <0x0 0x94 0x4 0x0 0x95 0x4 0x0 0x96 0x4>;
				power-domains = <0x7 0x18224072>;
				reg = <0x200 0x0 0x1 0x0>;
				xlnx,columns = <0x0 0x32>;
				xlnx,node-id = <0x18800000>;
			};
		};

		axi_dbg_hub@20205800000 {
			status = "disabled";
			clock-names = "aclk";
			clocks = <0x3 0x43>;
			compatible = "xlnx,axi-dbg-hub-2.0";
			reg = <0x202 0x5800000 0x0 0x200000>;
			xlnx,addr-offset = <0x202 0x5800000>;
			xlnx,addr-range = <0x200000>;
			xlnx,axi-addr-width = <0x40>;
			xlnx,axi-data-width = <0x80>;
			xlnx,axi-id-width = <0x2>;
			xlnx,axis-tdata-width = <0x20>;
			xlnx,num-debug-cores = <0x0>;
			xlnx,num-rd-outstanding-txn = <0x1>;
			xlnx,num-wr-outstanding-txn = <0x1>;
		};

		gpio@20200000000 {
			status = "disabled";
			#gpio-cells = <0x2>;
			clock-names = "s_axi_aclk";
			clocks = <0x3 0x41>;
			compatible = "xlnx,axi-gpio-2.0", "xlnx,xps-gpio-1.00.a";
			gpio-controller;
			reg = <0x202 0x0 0x0 0x1000>;
			xlnx,all-inputs = <0x0>;
			xlnx,all-inputs-2 = <0x0>;
			xlnx,all-outputs = <0x0>;
			xlnx,all-outputs-2 = <0x0>;
			xlnx,dout-default = <0x0>;
			xlnx,dout-default-2 = <0x0>;
			xlnx,gpio-width = <0x1>;
			xlnx,gpio2-width = <0x20>;
			xlnx,interrupt-present = <0x0>;
			xlnx,is-dual = <0x0>;
			xlnx,tri-default = <0xffffffff>;
			xlnx,tri-default-2 = <0xffffffff>;
		};

		axi_bram_ctrl@20204000000 {
			status = "disabled";
			clock-names = "s_axi_aclk";
			clocks = <0xf>;
			compatible = "xlnx,axi-bram-ctrl-4.1";
			reg = <0x202 0x4000000 0x0 0x20000>;
			xlnx,bram-addr-width = <0xb>;
			xlnx,bram-inst-mode = "EXTERNAL";
			xlnx,ecc = <0x0>;
			xlnx,ecc-onoff-reset-value = <0x0>;
			xlnx,ecc-type = <0x0>;
			xlnx,fault-inject = <0x0>;
			xlnx,memory-depth = <0x800>;
			xlnx,rd-cmd-optimization = <0x0>;
			xlnx,read-latency = <0x1>;
			xlnx,s-axi-ctrl-addr-width = <0x20>;
			xlnx,s-axi-ctrl-data-width = <0x20>;
			xlnx,s-axi-id-width = <0x1>;
			xlnx,s-axi-supports-narrow-burst = <0x0>;
			xlnx,single-port-bram = <0x1>;
		};

		misc_clk_0 {
			#clock-cells = <0x0>;
			clock-frequency = <0x11e19747>;
			compatible = "fixed-clock";
			phandle = <0xf>;
		};

		aie_core_ref_clk_0 {
			#clock-cells = <0x0>;
			clock-frequency = <0x4a817c80>;
			compatible = "fixed-clock";
			phandle = <0xe>;
		};
	};

	chosen {
		bootargs = "console=ttyUL0  earlycon=uartlite_a,0x402020000,115200n8 clk_ignore_unused root=/dev/mmcblk0p2 rw rootwait";
		stdout-path = "serial0:115200n8";
	};

	aliases {
		serial0 = "/amba_pl@0/serial@402020000";
		i2c0 = "/amba/i2c@ff020000";
		i2c1 = "/amba/i2c@ff030000";
		spi0 = "/amba/spi@f1010000";
	};

	memory@C080000000 {
		device_type = "memory";
		reg = <0x0 0x0 0x0 0x35ff0000 0xc0 0x80000000 0x3 0x80000000>;
	};

	reserved-memory {
		#address-cells = <0x2>;
		#size-cells = <0x2>;
		ranges;

		buffer@0 {
			no-map;
			reg = <0xc1 0x00000000 0x3 0x00000000>;
			phandle = <0x12>;
		};

		buffer0@36000000 {
			no-map;
			reg = <0x0 0x36000000 0x0 0x1000000>;
			phandle = <0x13>;
		};

		buffer@37000000 {
			no-map;
			reg = <0x0 0x37000000 0x0 0x1000000>;
			phandle = <0x14>;
		};
	};

	zyxclmm_drm {
		compatible = "xlnx,zocl-versal";
		status = "okay";
		memory-region = <0x12>;
		reg = <0x202 0x0 0x0 0x100000>;
	};

	ert_hw {
		compatible = "xlnx,embedded_sched_versal";
		status = "okay";
		xlnx,xgq_buffer = <0x13>;
		xlnx,xgq_device = <0x3d 0x3c 0x3b 0x3a>;
		interrupt-names = "irq_sq";
	};

	rpu-channel {
		compatible = "xlnx,rpu-channel";
		xlnx,xgq_buffer = <0x14>;
		xlnx,xgq_device = <0x3f>;
		interrupt-names = "irq_sq";
	};
};
